# PIC32CX1012BZ24032 register map
Vendor: Microchip Technology; Series: BZ24; File version: 0
CPU: CM4 r0p1, little endian, MPU, FPU, 3 interrupt priority bits
Registers are 32-bit, read-write, reset 0x0 unless marked. A register's access mark holds for its fields unless they carry their own. Offsets are from the block's base; [hi:lo] are bit positions; {n}, {i} and the like mark numbered series.

## DWT — Data Watchpoint and Trace Register
Base 0xE0001000; register names take the prefix DWT_
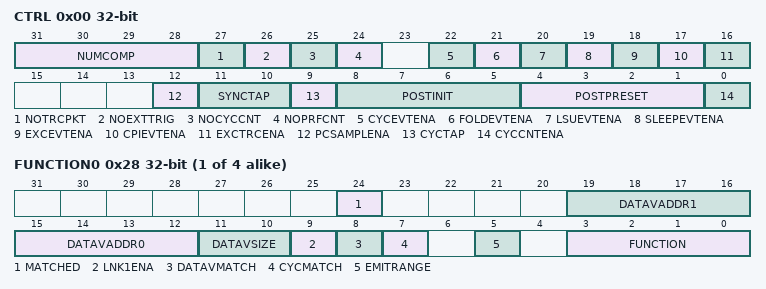
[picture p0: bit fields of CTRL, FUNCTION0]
0x00 CTRL — Control Register
  [31:28] NUMCOMP, [27] NOTRCPKT, [26] NOEXTTRIG, [25] NOCYCCNT, [24] NOPRFCNT, [22] CYCEVTENA, [21] FOLDEVTENA, [20] LSUEVTENA, [19] SLEEPEVTENA, [18] EXCEVTENA, [17] CPIEVTENA, [16] EXCTRCENA, [12] PCSAMPLENA, [11:10] SYNCTAP, [9] CYCTAP, [8:5] POSTINIT, [4:1] POSTPRESET, [0] CYCCNTENA
0x04 CYCCNT — Cycle Count Register
0x08 CPICNT — CPI Count Register
  [7:0] CPICNT
0x0C EXCCNT — Exception Overhead Count Register
  [7:0] EXCCNT
0x10 SLEEPCNT — Sleep Count Register
  [7:0] SLEEPCNT
0x14 LSUCNT — LSU Count Register
  [7:0] LSUCNT
0x18 FOLDCNT — Folded-instruction Count Register
  [7:0] FOLDCNT
0x1C PCSR ro — Program Counter Sample Register
{0x20+0x10*i} COMP{i} (i=0..3) — Comparator Register {i}
{0x24+0x10*i} MASK{i} (i=0..3) — Mask Register {i}
  [4:0] MASK
{0x28+0x10*i} FUNCTION{i} (i=0..3) — Function Register {i}
  [24] MATCHED, [19:16] DATAVADDR1, [15:12] DATAVADDR0, [11:10] DATAVSIZE, [9] LNK1ENA, [8] DATAVMATCH, [7] CYCMATCH, [5] EMITRANGE, [3:0] FUNCTION

## ETM — Embedded Trace Macrocell
Base 0xE0041000; register names take the prefix ETM_
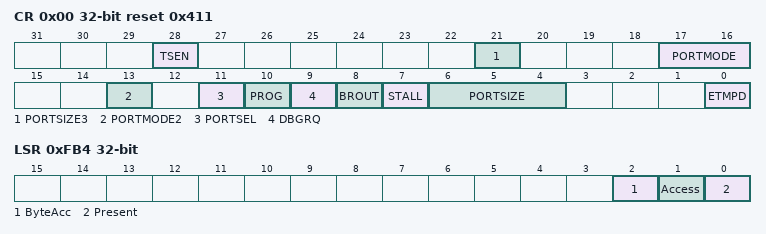
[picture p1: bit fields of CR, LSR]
0x00 CR reset 0x411 — ETM Main Control Register
  [28] TSEN — TimeStamp Enable
  [21] PORTSIZE3 — Port Size bit 3
  [17:16] PORTMODE — Port Mode bits 1:0
  [13] PORTMODE2 — Port Mode bit 2
  [11] PORTSEL — ETM Port Select
  [10] PROG — ETM Programming
  [9] DBGRQ — Debug Request Control
  [8] BROUT — Branch Output
  [7] STALL — Stall Processor
  [6:4] PORTSIZE — Port Size bits 2:0
  [0] ETMPD — ETM Power Down
0x04 CCR ro reset 0x8C802000 — ETM Configuration Code Register
0x08 TRIGGER — ETM Trigger Event Register
0x10 SR — ETM Status Register
0x14 SCR ro reset 0x20D09 — ETM System Configuration Register
0x20 TEEVR — ETM TraceEnable Event Register
0x24 TECR1 — ETM TraceEnable Control 1 Register
0x28 FFLR — ETM FIFO Full Level Register
0x140 CNTRLDVR1 — ETM Free-running Counter Reload Value
0x1E0 SYNCFR ro reset 0x400 — ETM Synchronization Frequency Register
0x1E4 IDR ro reset 0x4114F250 — ETM ID Register
0x1E8 CCER ro reset 0x18541800 — ETM Configuration Code Extension Register
0x1F0 TESSEICR — ETM TraceEnable Start/Stop EmbeddedICE Control Register
0x1F8 TSEVT — ETM TimeStamp Event Register
0x200 TRACEIDR — ETM CoreSight Trace ID Register
0x208 IDR2 ro — ETM ID Register 2
0x314 PDSR ro reset 0x1 — ETM Device Power-Down Status Register
0xEE0 ITMISCIN ro — ETM Integration Test Miscellaneous Inputs
0xEE8 ITTRIGOUT wo — ETM Integration Test Trigger Out
0xEF0 ITATBCTR2 ro — ETM Integration Test ATB Control 2
0xEF8 ITATBCTR0 wo — ETM Integration Test ATB Control 0
0xF00 ITCTRL — ETM Integration Mode Control Register
  [0] INTEGRATION
0xFA0 CLAIMSET — ETM Claim Tag Set Register
0xFA4 CLAIMCLR — ETM Claim Tag Clear Register
0xFB0 LAR wo — ETM Lock Access Register
0xFB4 LSR ro — ETM Lock Status Register
  [2] ByteAcc, [1] Access, [0] Present
0xFB8 AUTHSTATUS ro — ETM Authentication Status Register
0xFCC DEVTYPE ro reset 0x13 — ETM CoreSight Device Type Register
0xFD0 PIDR4 ro reset 0x4 — ETM Peripheral Identification Register #4
{0xFC0+4i} PIDR{i} ro (i=5..7) — ETM Peripheral Identification Register #{i}
0xFE0 PIDR0 ro reset 0x25 — ETM Peripheral Identification Register #0
0xFE4 PIDR1 ro reset 0xB9 — ETM Peripheral Identification Register #1
0xFE8 PIDR2 ro reset 0xB — ETM Peripheral Identification Register #2
0xFEC PIDR3 ro — ETM Peripheral Identification Register #3
0xFF0 CIDR0 ro reset 0xD — ETM Component Identification Register #0
0xFF4 CIDR1 ro reset 0x90 — ETM Component Identification Register #1
0xFF8 CIDR2 ro reset 0x5 — ETM Component Identification Register #2
0xFFC CIDR3 ro reset 0xB1 — ETM Component Identification Register #3
